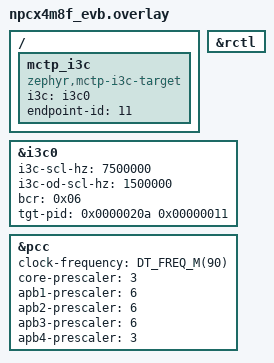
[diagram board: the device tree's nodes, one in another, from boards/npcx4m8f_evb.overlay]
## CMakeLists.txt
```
# SPDX-FileCopyrightText: Copyright The Zephyr Project Contributors
# SPDX-License-Identifier: Apache-2.0
cmake_minimum_required(VERSION 3.20.0)

find_package(Zephyr REQUIRED HINTS $ENV{ZEPHYR_BASE})
project(spdm_responder_i3c)

target_sources(app PRIVATE
  src/main.c
  ${CMAKE_CURRENT_LIST_DIR}/../common/sample_ecp256.c
  ${CMAKE_CURRENT_LIST_DIR}/../common/sample_app_message.c
)
target_include_directories(app PRIVATE ${CMAKE_CURRENT_LIST_DIR}/../common)
```

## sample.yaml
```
# SPDX-FileCopyrightText: Copyright The Zephyr Project Contributors
# SPDX-License-Identifier: Apache-2.0
sample:
  description: libspdm SPDM responder over MCTP on I3C
  name: libspdm responder I3C
tests:
  sample.lib.libspdm.responder_i3c.build:
    build_only: true
    tags: libspdm i3c mctp
    platform_allow: npcx4m8f_evb
    integration_platforms:
      - npcx4m8f_evb
```

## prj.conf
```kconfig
# SPDX-FileCopyrightText: Copyright The Zephyr Project Contributors
# SPDX-License-Identifier: Apache-2.0

# libspdm: responder only, MCTP transport + libmctp bridge.
CONFIG_LIBSPDM=y
CONFIG_LIBSPDM_REQUESTER=n
CONFIG_LIBSPDM_RESPONDER=y
CONFIG_LIBSPDM_CRYPTO_MBEDTLS=y
CONFIG_LIBSPDM_TRANSPORT_MCTP=y
CONFIG_LIBSPDM_TRANSPORT_MCTP_LIBMCTP_BRIDGE=y
CONFIG_LIBSPDM_SECRET_LIB_SAMPLE=y
# Disable libspdm's internal hex-dump prints. The flow is now stable;
# every byte of every SPDM message logged over serial dominates the
# round-trip time on the I3C link (and overflows the log subsystem
# buffer). The application-level LOG_INF calls still trace each phase.
CONFIG_LIBSPDM_DEBUG_ENABLE=n

# MCTP bridge sized for ECDSA-P256 CHALLENGE_AUTH: the largest message
# is GET_CERTIFICATE (~1.5 KiB chain) which we cap with
# LIBSPDM_MAX_CERT_CHAIN_SIZE=0x800 in the module CMakeLists. Round up
# to 2 KiB to leave headroom for the spdm_cert_chain_t header and the
# MCTP framing.
CONFIG_LIBSPDM_MCTP_BUFFER_SIZE=2048
CONFIG_LIBSPDM_MCTP_RX_QUEUE_DEPTH=1

# Zephyr libmctp + I3C target binding.
CONFIG_I3C=y
CONFIG_MCTP=y
CONFIG_MCTP_I3C_TARGET=y

# A full SPDM_CERTIFICATE response (cert chain plus spdm_cert_chain_t
# header) is ~1.4 KiB, so the default 1 KiB libmctp reassembly cap
# rejects it with -ENOMEM at mctp_message_tx. Size both message and
# heap to comfortably hold our worst-case 2 KiB transfer, with enough
# slack in the heap to hold one TX and one RX reassembly buffer plus
# the libmctp context overhead.
CONFIG_MCTP_MAX_MESSAGE_SIZE=2048
CONFIG_MCTP_HEAP_SIZE=6144

# RNG: npcx4 has no hardware DRBG, so we fall back to Zephyr's
# k_cycle_get_32-driven TIMER_RANDOM_GENERATOR (auto-selected by
# CONFIG_TEST_RANDOM_GENERATOR=y). NOT suitable for production --
# real deployments must wire a real entropy source.
CONFIG_TEST_RANDOM_GENERATOR=y

CONFIG_MAIN_STACK_SIZE=4096
# mbedtls X.509 + ECDSA verify can request ~10-12 KiB of transient
# malloc traffic; size both arenas with that working set in mind.
CONFIG_HEAP_MEM_POOL_SIZE=8192
CONFIG_COMMON_LIBC_MALLOC=y
CONFIG_COMMON_LIBC_MALLOC_ARENA_SIZE=16384

CONFIG_LOG=y
CONFIG_LOG_BUFFER_SIZE=4096
CONFIG_PRINTK=y
```

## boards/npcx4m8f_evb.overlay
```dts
/*
 * SPDX-FileCopyrightText: Copyright The Zephyr Project Contributors
 * SPDX-License-Identifier: Apache-2.0
 *
 * I3C target-side overlay for the libspdm SPDM responder sample on
 * the Nuvoton NPCX4M8F EVB. Mirrors the wiring used by the upstream
 * samples/subsys/pmci/mctp/i3c_bus_endpoint overlay for the same
 * board.
 */

&rctl {
	status = "okay";
};

&i3c0 {
	status = "okay";
	i3c-scl-hz = <7500000>;
	i3c-od-scl-hz = <1500000>;

	bcr = <0x06>;
	tgt-pid = <0x0000020a 0x00000011>;
};

&pcc {
	clock-frequency = <DT_FREQ_M(90)>;
	core-prescaler = <3>;
	apb1-prescaler = <6>;
	apb2-prescaler = <6>;
	apb3-prescaler = <6>;
	apb4-prescaler = <3>;
};

/ {
	mctp_i3c: mctp_i3c {
		compatible = "zephyr,mctp-i3c-target";
		i3c = <&i3c0>;
		endpoint-id = <11>;
	};
};
```

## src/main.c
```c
/*
 * SPDX-FileCopyrightText: Copyright The Zephyr Project Contributors
 * SPDX-License-Identifier: Apache-2.0
 *
 * SPDM responder sample over MCTP-on-I3C. Pairs with
 * samples/spdm_requester_i3c flashed onto a second board on the same
 * I3C bus. This sample runs a single SPDM responder context whose
 * dispatcher loops on libspdm_responder_dispatch_message() until the
 * peer goes silent.
 */

#include <stdint.h>
#include <stdlib.h>
#include <string.h>

#include <zephyr/kernel.h>
#include <zephyr/logging/log.h>

#include <libmctp.h>
#include <zephyr/pmci/mctp/mctp_i3c_target.h>

#include "library/spdm_common_lib.h"
#include "library/spdm_responder_lib.h"
#include "library/spdm_transport_mctp_lib.h"
#include "internal/libspdm_device_secret_lib.h"
#include "hal/library/memlib.h"
#include "industry_standard/spdm.h"

#include "libspdm/zephyr/spdm_mctp_io.h"
#include <libspdm/zephyr/secret_blob.h>

#include "sample_ecp256.h"

LOG_MODULE_REGISTER(spdm_responder_i3c, LOG_LEVEL_INF);

#define PEER_EID 20U

/* See requester sample for the reasoning behind this expression. */
#define LIBSPDM_MAX_SPDM_MSG_SIZE  (CONFIG_LIBSPDM_MCTP_BUFFER_SIZE - \
				    LIBSPDM_MCTP_TRANSPORT_HEADER_SIZE - \
				    LIBSPDM_MCTP_TRANSPORT_TAIL_SIZE)

MCTP_I3C_TARGET_DT_DEFINE(mctp_i3c_tgt, DT_NODELABEL(mctp_i3c));

static struct spdm_mctp_io spdm_io;
static uint8_t spdm_scratch[26496] __aligned(8);

static int configure_spdm(void *spdm_ctx)
{
	libspdm_data_parameter_t param;
	spdm_version_number_t version;
	uint8_t  u8;
	uint32_t u32;
	uint16_t u16;

	memset(&param, 0, sizeof(param));
	param.location = LIBSPDM_DATA_LOCATION_LOCAL;

	/*
	 * LIBSPDM_DATA_SPDM_VERSION expects an array of
	 * spdm_version_number_t (uint16_t), with the SPDM version byte
	 * placed in the high byte (SPDM_VERSION_NUMBER_SHIFT_BIT = 8).
	 */
	version = (spdm_version_number_t)SPDM_MESSAGE_VERSION_12
		  << SPDM_VERSION_NUMBER_SHIFT_BIT;
	if (libspdm_set_data(spdm_ctx, LIBSPDM_DATA_SPDM_VERSION, &param,
			     &version, sizeof(version)) != LIBSPDM_STATUS_SUCCESS) {
		return -1;
	}

	/* CT_EXPONENT advertises the worst-case crypto response time as
	 * 2^CT microseconds. The responder runs ECDH keygen + ECDSA
	 * sign + transcript hashing entirely in software on the
	 * Cortex-M4F (no PSA crypto accelerator on npcx4), so
	 * KEY_EXCHANGE can take well over a second; CT=22 (~4.2 s)
	 * gives the requester ample headroom over MCTP-on-I3C without
	 * being absurdly large.
	 */
	u8 = 22U;
	(void)libspdm_set_data(spdm_ctx, LIBSPDM_DATA_CAPABILITY_CT_EXPONENT,
			       &param, &u8, sizeof(u8));

	u32 = SPDM_GET_CAPABILITIES_RESPONSE_FLAGS_CERT_CAP |
	      SPDM_GET_CAPABILITIES_RESPONSE_FLAGS_CHAL_CAP;
	if (libspdm_set_data(spdm_ctx, LIBSPDM_DATA_CAPABILITY_FLAGS, &param,
			     &u32, sizeof(u32)) != LIBSPDM_STATUS_SUCCESS) {
		return -1;
	}

	u8 = 0U;
	(void)libspdm_set_data(spdm_ctx, LIBSPDM_DATA_MEASUREMENT_SPEC,
			       &param, &u8, sizeof(u8));

	u32 = SPDM_ALGORITHMS_BASE_ASYM_ALGO_TPM_ALG_ECDSA_ECC_NIST_P256;
	(void)libspdm_set_data(spdm_ctx, LIBSPDM_DATA_BASE_ASYM_ALGO, &param,
			       &u32, sizeof(u32));

	u32 = SPDM_ALGORITHMS_BASE_HASH_ALGO_TPM_ALG_SHA_256;
	(void)libspdm_set_data(spdm_ctx, LIBSPDM_DATA_BASE_HASH_ALGO, &param,
			       &u32, sizeof(u32));

	u16 = SPDM_ALGORITHMS_DHE_NAMED_GROUP_SECP_256_R1;
	(void)libspdm_set_data(spdm_ctx, LIBSPDM_DATA_DHE_NAME_GROUP, &param,
			       &u16, sizeof(u16));

	u16 = SPDM_ALGORITHMS_AEAD_CIPHER_SUITE_AES_256_GCM;
	(void)libspdm_set_data(spdm_ctx, LIBSPDM_DATA_AEAD_CIPHER_SUITE,
			       &param, &u16, sizeof(u16));

	u16 = SPDM_ALGORITHMS_BASE_ASYM_ALGO_TPM_ALG_ECDSA_ECC_NIST_P256;
	(void)libspdm_set_data(spdm_ctx, LIBSPDM_DATA_REQ_BASE_ASYM_ALG,
			       &param, &u16, sizeof(u16));

	u16 = SPDM_ALGORITHMS_KEY_SCHEDULE_SPDM;
	(void)libspdm_set_data(spdm_ctx, LIBSPDM_DATA_KEY_SCHEDULE, &param,
			       &u16, sizeof(u16));

	u8 = SPDM_ALGORITHMS_OPAQUE_DATA_FORMAT_1;
	(void)libspdm_set_data(spdm_ctx, LIBSPDM_DATA_OTHER_PARAMS_SUPPORT,
			       &param, &u8, sizeof(u8));

	return 0;
}

#ifdef CONFIG_LIBSPDM_CRYPTO_MBEDTLS
static int install_responder_cert_chain(void *spdm_ctx)
{
	libspdm_data_parameter_t param;
	void *cert_chain = NULL;
	size_t cert_chain_size = 0;
	uint8_t u8;
	bool res;

	res = libspdm_read_responder_public_certificate_chain(
		SPDM_ALGORITHMS_BASE_HASH_ALGO_TPM_ALG_SHA_256,
		SPDM_ALGORITHMS_BASE_ASYM_ALGO_TPM_ALG_ECDSA_ECC_NIST_P256,
		&cert_chain, &cert_chain_size, NULL, NULL);
	if (!res || cert_chain == NULL) {
		LOG_ERR("failed to load responder cert chain");
		return -1;
	}

	memset(&param, 0, sizeof(param));
	param.location = LIBSPDM_DATA_LOCATION_LOCAL;
	param.additional_data[0] = 0; /* slot 0 */
	(void)libspdm_set_data(spdm_ctx, LIBSPDM_DATA_LOCAL_PUBLIC_CERT_CHAIN,
			       &param, cert_chain, cert_chain_size);
	/* libspdm_set_data stores the pointer for LOCAL_PUBLIC_CERT_CHAIN
	 * (no internal copy), so cert_chain must outlive spdm_ctx. We
	 * intentionally leak the allocation -- it lives for the lifetime
	 * of the responder process.
	 */

	u8 = 1U << 0; /* only slot 0 populated */
	(void)libspdm_set_data(spdm_ctx, LIBSPDM_DATA_LOCAL_SUPPORTED_SLOT_MASK,
			       &param, &u8, sizeof(u8));
	return 0;
}
#endif

int main(void)
{
	struct mctp *mctp_ctx;
	void *spdm_ctx;
	size_t ctx_size;
	libspdm_return_t status;
	int rc;
	uint8_t local_eid = mctp_i3c_tgt.endpoint_id;

	LOG_INF("SPDM responder (libspdm + libmctp + I3C) on %s",
		CONFIG_BOARD_TARGET);
	LOG_INF("local EID=%u, peer EID=%u", local_eid, PEER_EID);

	mctp_ctx = mctp_init();
	__ASSERT_NO_MSG(mctp_ctx != NULL);
	mctp_register_bus(mctp_ctx, &mctp_i3c_tgt.binding, local_eid);

	rc = spdm_mctp_io_init(&spdm_io, mctp_ctx, local_eid, PEER_EID);
	if (rc != 0) {
		LOG_ERR("spdm_mctp_io_init failed: %d", rc);
		return rc;
	}

	ctx_size = libspdm_get_context_size();
	spdm_ctx = k_malloc(ctx_size);
	__ASSERT_NO_MSG(spdm_ctx != NULL);

	libspdm_init_context(spdm_ctx);

	rc = spdm_mctp_io_register(spdm_ctx, &spdm_io);
	if (rc != 0) {
		LOG_ERR("spdm_mctp_io_register failed: %d", rc);
		return rc;
	}

	libspdm_register_transport_layer_func(spdm_ctx,
		LIBSPDM_MAX_SPDM_MSG_SIZE,
		LIBSPDM_MCTP_TRANSPORT_HEADER_SIZE,
		LIBSPDM_MCTP_TRANSPORT_TAIL_SIZE,
		libspdm_transport_mctp_encode_message,
		libspdm_transport_mctp_decode_message);

	libspdm_set_scratch_buffer(spdm_ctx, spdm_scratch, sizeof(spdm_scratch));

	if (configure_spdm(spdm_ctx) != 0) {
		LOG_ERR("configure_spdm failed");
		return -1;
	}

#ifdef CONFIG_LIBSPDM_CRYPTO_MBEDTLS
	if (libspdm_zephyr_secret_blob_register(sample_ecp256_blobs) != 0) {
		LOG_ERR("secret blob registration failed");
		return -1;
	}
	if (install_responder_cert_chain(spdm_ctx) != 0) {
		return -1;
	}
#endif

	LOG_INF("entering responder dispatch loop");
	while (true) {
		status = libspdm_responder_dispatch_message(spdm_ctx);
		if (status == LIBSPDM_STATUS_SUCCESS) {
			continue;
		}
		if (status == LIBSPDM_STATUS_RECEIVE_FAIL) {
			/*
			 * Receive timed out: peer is silent. Loop and keep
			 * listening; this is the steady-state for a
			 * responder waiting for the next requester
			 * exchange.
			 */
			continue;
		}
		LOG_WRN("dispatch returned 0x%x", status);
	}

	return 0;
}
```
